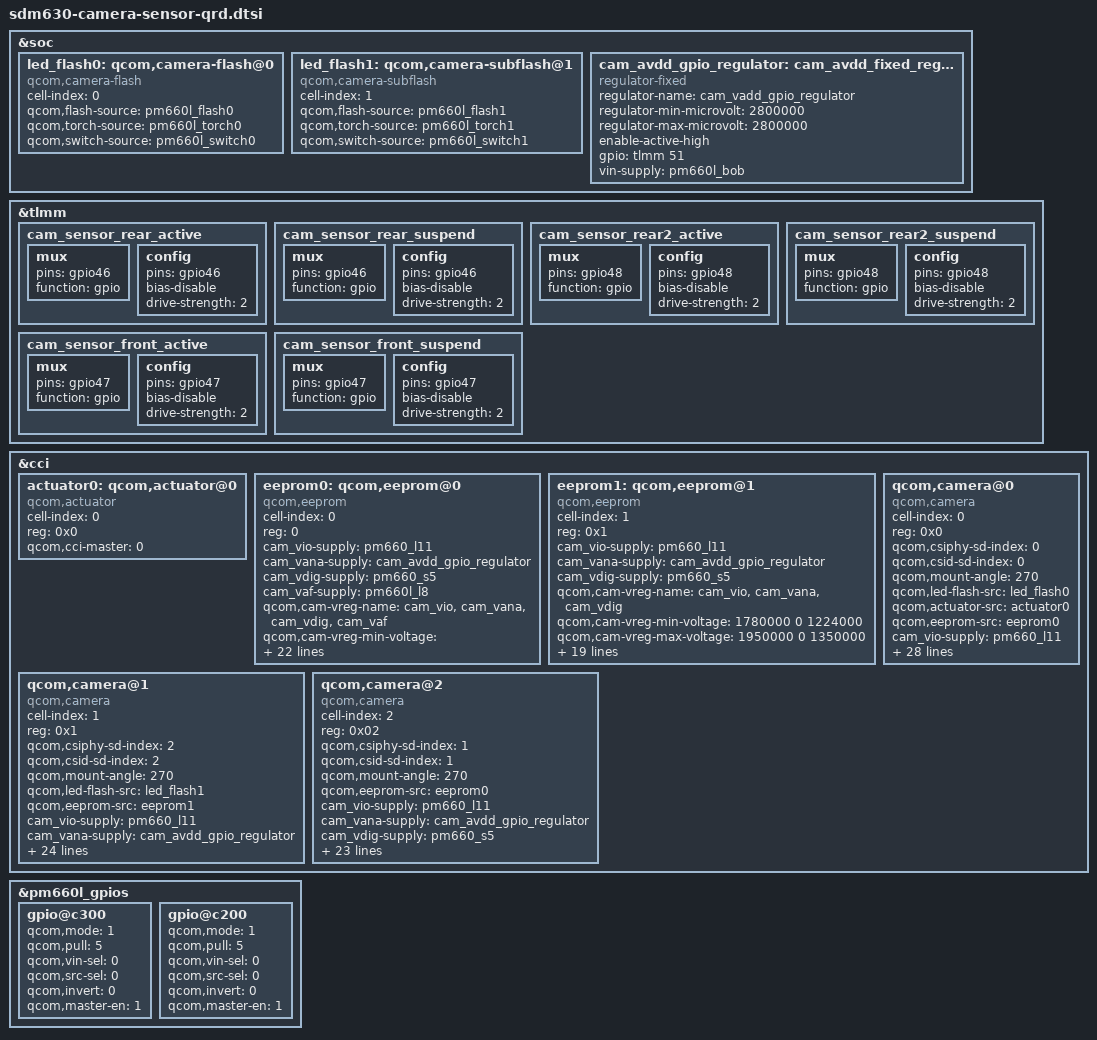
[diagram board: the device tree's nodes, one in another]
/*
 * Copyright (c) 2017, The Linux Foundation. All rights reserved.
 *
 * This program is free software; you can redistribute it and/or modify
 * it under the terms of the GNU General Public License version 2 and
 * only version 2 as published by the Free Software Foundation.
 *
 * This program is distributed in the hope that it will be useful,
 * but WITHOUT ANY WARRANTY; without even the implied warranty of
 * MERCHANTABILITY or FITNESS FOR A PARTICULAR PURPOSE.  See the
 * GNU General Public License for more details.
 */

&soc {

	led_flash0: qcom,camera-flash@0 {
		cell-index = <0>;
		compatible = "qcom,camera-flash";
		qcom,flash-source = <&pm660l_flash0>;
		qcom,torch-source = <&pm660l_torch0>;
		qcom,switch-source = <&pm660l_switch0>;
		status = "ok";
	};


	led_flash1: qcom,camera-subflash@1 {
		cell-index = <1>;
		compatible = "qcom,camera-subflash";
		qcom,flash-source = <&pm660l_flash1>;
		qcom,torch-source = <&pm660l_torch1>;
		qcom,switch-source = <&pm660l_switch1>;
		status = "ok";
	};


	cam_avdd_gpio_regulator: cam_avdd_fixed_regulator {
		compatible = "regulator-fixed";
		regulator-name = "cam_vadd_gpio_regulator";
		regulator-min-microvolt = <2800000>;
		regulator-max-microvolt = <2800000>;
		enable-active-high;
		gpio = <&tlmm 51 0>;
		vin-supply = <&pm660l_bob>;
	};

/*
	cam_vaf_gpio_regulator: cam_vaf_fixed_regulator {
		compatible = "regulator-fixed";
		regulator-name = "cam_vaf_gpio_regulator";
		regulator-min-microvolt = <2800000>;
		regulator-max-microvolt = <2800000>;
		enable-active-high;
		gpio = <&tlmm 50 0>;
		vin-supply = <&pm660l_bob>;
	};
*/
};

&tlmm {
	cam_sensor_rear_active: cam_sensor_rear_active {
		/* RESET */
		mux {
			pins = "gpio46";
			function = "gpio";
		};

		config {
			pins = "gpio46";
			bias-disable; /* No PULL */
			drive-strength = <2>; /* 2 MA */
		};
	};

	cam_sensor_rear_suspend: cam_sensor_rear_suspend {
		/* RESET */
		mux {
			pins = "gpio46";
			function = "gpio";
		};

		config {
			pins = "gpio46";
			bias-disable; /* No PULL */
			drive-strength = <2>; /* 2 MA */
		};
	};

	cam_sensor_rear2_active: cam_sensor_rear2_active {
		/* RESET */
		mux {
			pins = "gpio48";
			function = "gpio";
		};

		config {
			pins = "gpio48";
			bias-disable; /* No PULL */
			drive-strength = <2>; /* 2 MA */
		};
	};

	cam_sensor_rear2_suspend: cam_sensor_rear2_suspend {
		/* RESET */
		mux {
			pins = "gpio48";
			function = "gpio";
		};

		config {
			pins = "gpio48";
			bias-disable; /* No PULL */
			drive-strength = <2>; /* 2 MA */
		};
	};

	cam_sensor_front_active: cam_sensor_front_active {
		/* RESET */
		mux {
			pins = "gpio47";
			function = "gpio";
		};

		config {
			pins = "gpio47";
			bias-disable; /* No PULL */
			drive-strength = <2>; /* 2 MA */
		};
	};

	cam_sensor_front_suspend: cam_sensor_front_suspend {
		/* RESET */
		mux {
			pins = "gpio47";
			function = "gpio";
		};

		config {
			pins = "gpio47";
			bias-disable; /* No PULL */
			drive-strength = <2>; /* 2 MA */
		};
	};
};

&cci {
	actuator0: qcom,actuator@0 {
		cell-index = <0>;
		reg = <0x0>;
		compatible = "qcom,actuator";
		qcom,cci-master = <0>;
	};
/*
	actuator1: qcom,actuator@1 {
		cell-index = <1>;
		reg = <0x1>;
		compatible = "qcom,actuator";
		qcom,cci-master = <1>;
		cam_vaf-supply = <&cam_vaf_gpio_regulator>;
		qcom,cam-vreg-name = "cam_vaf";
		qcom,cam-vreg-min-voltage = <2800000>;
		qcom,cam-vreg-max-voltage = <2800000>;
		qcom,cam-vreg-op-mode = <0>;
	};

	ois0: qcom,ois {
		cell-index = <0>;
		compatible = "qcom,ois";
		qcom,cci-master = <0>;
		cam_vaf-supply = <&cam_vaf_gpio_regulator>;
		qcom,cam-vreg-name = "cam_vaf";
		qcom,cam-vreg-min-voltage = <2800000>;
		qcom,cam-vreg-max-voltage = <2800000>;
		qcom,cam-vreg-op-mode = <0>;
		status = "disabled";
	};
*/
	eeprom0: qcom,eeprom@0 {
		cell-index = <0>;
		reg = <0>;
		compatible = "qcom,eeprom";
		cam_vio-supply = <&pm660_l11>;
		cam_vana-supply = <&cam_avdd_gpio_regulator>;
		cam_vdig-supply = <&pm660_s5>;
		cam_vaf-supply = <&pm660l_l8>;
		qcom,cam-vreg-name = "cam_vio", "cam_vana", "cam_vdig", "cam_vaf";
		qcom,cam-vreg-min-voltage = <1780000 0 1224000 2800000>;
		qcom,cam-vreg-max-voltage = <1950000 0 1350000 2800000>;
		qcom,cam-vreg-op-mode = <105000 0 105000 100000>;
		qcom,gpio-no-mux = <0>;
		pinctrl-names = "cam_default", "cam_suspend";
		pinctrl-0 = <&cam_sensor_mclk0_active
				 &cam_sensor_rear_active>;
		pinctrl-1 = <&cam_sensor_mclk0_suspend
				 &cam_sensor_rear_suspend>;
		gpios = <&tlmm 32 0>,
			<&tlmm 46 0>,
			<&pm660l_gpios 4 0>;
		qcom,gpio-reset = <1>;
		qcom,gpio-vdig = <2>;
		qcom,gpio-req-tbl-num = <0 1 2>;
		qcom,gpio-req-tbl-flags = <1 0 0>;
		qcom,gpio-req-tbl-label = "CAMIF_MCLK0",
					"CAM_RESET0",
					"CAM_VDIG0";
		qcom,sensor-position = <0>;
		qcom,sensor-mode = <0>;
		qcom,cci-master = <0>;
		status = "ok";
		clocks = <&clock_mmss MCLK0_CLK_SRC>,
				<&clock_mmss MMSS_CAMSS_MCLK0_CLK>;
		clock-names = "cam_src_clk", "cam_clk";
		qcom,clock-rates = <24000000 0>;
	};

	eeprom1: qcom,eeprom@1 {
		cell-index = <1>;
		reg = <0x1>;
		compatible = "qcom,eeprom";
		cam_vio-supply = <&pm660_l11>;
		cam_vana-supply = <&cam_avdd_gpio_regulator>;
		cam_vdig-supply = <&pm660_s5>;
		qcom,cam-vreg-name = "cam_vio", "cam_vana", "cam_vdig";
		qcom,cam-vreg-min-voltage = <1780000 0 1224000>;
		qcom,cam-vreg-max-voltage = <1950000 0 1350000>;
		qcom,cam-vreg-op-mode = <105000 0 105000>;
		qcom,gpio-no-mux = <0>;
		pinctrl-names = "cam_default", "cam_suspend";
		pinctrl-0 = <&cam_sensor_mclk1_active
				 &cam_sensor_front_active>;
		pinctrl-1 = <&cam_sensor_mclk1_suspend
				 &cam_sensor_front_suspend>;
		gpios = <&tlmm 33 0>,
			<&tlmm 47 0>,
			<&pm660l_gpios 3 0>;
		qcom,gpio-reset = <1>;
		qcom,gpio-vdig = <2>;
		qcom,gpio-req-tbl-num = <0 1 2>;
		qcom,gpio-req-tbl-flags = <1 0 0>;
		qcom,gpio-req-tbl-label = "CAMIF_MCLK1",
					  "CAM_RESET1",
					  "CAM_VDIG1";
		qcom,sensor-position = <1>;
		qcom,sensor-mode = <0>;
		qcom,cci-master = <1>;
		status = "ok";
		clocks = <&clock_mmss MCLK1_CLK_SRC>,
			<&clock_mmss MMSS_CAMSS_MCLK1_CLK>;
		clock-names = "cam_src_clk", "cam_clk";
		qcom,clock-rates = <24000000 0>;
	};

/*
	eeprom2: qcom,eeprom@2 {
		cell-index = <2>;
		reg = <0x2>;
		compatible = "qcom,eeprom";
		cam_vio-supply = <&pm660_l11>;
		cam_vana-supply = <&cam_avdd_gpio_regulator>;
		cam_vdig-supply = <&pm660_s5>;
		qcom,cam-vreg-name = "cam_vio", "cam_vana", "cam_vdig";
		qcom,cam-vreg-min-voltage = <1780000 0 1352000>;
		qcom,cam-vreg-max-voltage = <1950000 0 1352000>;
		qcom,cam-vreg-op-mode = <105000 0 105000>;
		qcom,gpio-no-mux = <0>;
		pinctrl-names = "cam_default", "cam_suspend";
		pinctrl-0 = <&cam_sensor_mclk1_active
				 &cam_sensor_front_active>;
		pinctrl-1 = <&cam_sensor_mclk1_suspend
				 &cam_sensor_front_suspend>;
		gpios = <&tlmm 33 0>,
			<&tlmm 47 0>,
			<&pm660l_gpios 3 0>;
		qcom,gpio-reset = <1>;
		qcom,gpio-vdig = <2>;
		qcom,gpio-req-tbl-num = <0 1 2>;
		qcom,gpio-req-tbl-flags = <1 0 0>;
		qcom,gpio-req-tbl-label = "CAMIF_MCLK2",
					"CAM_RESET2",
					"CAM_VDIG";
		qcom,sensor-position = <1>;
		qcom,sensor-mode = <0>;
		qcom,cci-master = <1>;
		status = "ok";
		clocks = <&clock_mmss MCLK1_CLK_SRC>,
			<&clock_mmss MMSS_CAMSS_MCLK1_CLK>;
		clock-names = "cam_src_clk", "cam_clk";
		qcom,clock-rates = <24000000 0>;
	};
*/
	qcom,camera@0 {
		cell-index = <0>;
		compatible = "qcom,camera";
		reg = <0x0>;
		qcom,csiphy-sd-index = <0>;
		qcom,csid-sd-index = <0>;
		qcom,mount-angle = <270>;
		qcom,led-flash-src = <&led_flash0>;
		qcom,actuator-src = <&actuator0>;
		//qcom,ois-src = <&ois0>;
		qcom,eeprom-src = <&eeprom0>;
		cam_vio-supply = <&pm660_l11>;
		cam_vana-supply = <&cam_avdd_gpio_regulator>;
		cam_vdig-supply = <&pm660_s5>;
		cam_vaf-supply = <&pm660l_l8>;
		qcom,cam-vreg-name = "cam_vio", "cam_vana", "cam_vdig", "cam_vaf";
		/*Huaqin modify for af_vdd voltage by lizihao at 2015/02/05 start*/
		qcom,cam-vreg-min-voltage = <1780000 0 1224000 2800000>;
		qcom,cam-vreg-max-voltage = <1950000 0 1350000 2800000>;
		/*Huaqin modify for af_vdd voltage by lizihao at 2015/02/05 end*/
		qcom,cam-vreg-op-mode = <105000 0 105000 100000>;
		qcom,gpio-no-mux = <0>;
		pinctrl-names = "cam_default", "cam_suspend";
		pinctrl-0 = <&cam_sensor_mclk0_active
				 &cam_sensor_rear_active>;
		pinctrl-1 = <&cam_sensor_mclk0_suspend
				 &cam_sensor_rear_suspend>;
		gpios = <&tlmm 32 0>,
			<&tlmm 46 0>,
			<&pm660l_gpios 4 0>;
		qcom,gpio-reset = <1>;
		qcom,gpio-vdig = <2>;
		qcom,gpio-req-tbl-num = <0 1 2>;
		qcom,gpio-req-tbl-flags = <1 0 0>;
		qcom,gpio-req-tbl-label = "CAMIF_MCLK0",
					"CAM_RESET0",
					"CAM_VDIG0";
		qcom,sensor-position = <0>;
		qcom,sensor-mode = <0>;
		qcom,cci-master = <0>;
		status = "ok";
		clocks = <&clock_mmss MCLK0_CLK_SRC>,
				<&clock_mmss MMSS_CAMSS_MCLK0_CLK>;
		clock-names = "cam_src_clk", "cam_clk";
		qcom,clock-rates = <24000000 0>;
	};

	qcom,camera@1 {
		cell-index = <1>;
		compatible = "qcom,camera";
		reg = <0x1>;
		qcom,csiphy-sd-index = <2>;
		qcom,csid-sd-index = <2>;
		qcom,mount-angle = <270>;
		qcom,led-flash-src = <&led_flash1>;
		qcom,eeprom-src = <&eeprom1>;
		cam_vio-supply = <&pm660_l11>;
		cam_vana-supply = <&cam_avdd_gpio_regulator>;
		cam_vdig-supply = <&pm660_s5>;
		qcom,cam-vreg-name = "cam_vio", "cam_vana", "cam_vdig";
		/*Huaqin modify for af_vdd voltage by lizihao at 2015/02/05 start*/
		qcom,cam-vreg-min-voltage = <1780000 0 1224000>;
		qcom,cam-vreg-max-voltage = <1950000 0 1350000>;
		/*Huaqin modify for af_vdd voltage by lizihao at 2015/02/05 end*/
		qcom,cam-vreg-op-mode = <105000 0 105000>;
		qcom,gpio-no-mux = <0>;
		pinctrl-names = "cam_default", "cam_suspend";
		pinctrl-0 = <&cam_sensor_mclk1_active
				 &cam_sensor_front_active>;
		pinctrl-1 = <&cam_sensor_mclk1_suspend
				 &cam_sensor_front_suspend>;
		gpios = <&tlmm 33 0>,
			<&tlmm 47 0>,
			<&pm660l_gpios 3 0>;
		qcom,gpio-reset = <1>;
		qcom,gpio-vdig = <2>;
		qcom,gpio-req-tbl-num = <0 1 2>;
		qcom,gpio-req-tbl-flags = <1 0 0>;
		qcom,gpio-req-tbl-label = "CAMIF_MCLK1",
					  "CAM_RESET1",
					  "CAM_VDIG1";
		qcom,sensor-position = <1>;
		qcom,sensor-mode = <0>;
		qcom,cci-master = <1>;
		status = "ok";
		clocks = <&clock_mmss MCLK1_CLK_SRC>,
			<&clock_mmss MMSS_CAMSS_MCLK1_CLK>;
		clock-names = "cam_src_clk", "cam_clk";
		qcom,clock-rates = <24000000 0>;
	};

/* Huaqin modify for add sub camera dts config by lizihao at 2018/02/11 start*/
	qcom,camera@2 {
		cell-index = <2>;
		compatible = "qcom,camera";
		reg = <0x02>;
		qcom,csiphy-sd-index = <1>;
		qcom,csid-sd-index = <1>;
		qcom,mount-angle = <270>;
		/* Huaqin add for gc5025 eeprom by lizihao at 2018/03/23 start*/
		qcom,eeprom-src = <&eeprom0>;
		/* Huaqin add for gc5025 eeprom by lizihao at 2018/03/23 end*/
		cam_vio-supply = <&pm660_l11>;
		cam_vana-supply = <&cam_avdd_gpio_regulator>;
		cam_vdig-supply = <&pm660_s5>;
		qcom,cam-vreg-name = "cam_vio", "cam_vana", "cam_vdig";
		qcom,cam-vreg-min-voltage = <1780000 0 1224000>;
		qcom,cam-vreg-max-voltage = <1950000 0 1350000>;
		qcom,cam-vreg-op-mode = <105000 0 105000>;
		qcom,gpio-no-mux = <0>;
		pinctrl-names = "cam_default", "cam_suspend";
		pinctrl-0 = <&cam_sensor_mclk3_active
				 &cam_sensor_rear2_active>;
		pinctrl-1 = <&cam_sensor_mclk3_suspend
				 &cam_sensor_rear2_suspend>;
		gpios = <&tlmm 35 0>,
			<&tlmm 48 0>,
			<&pm660l_gpios 4 0>;
		qcom,gpio-reset = <1>;
		qcom,gpio-vdig = <2>;
		qcom,gpio-req-tbl-num = <0 1 2>;
		qcom,gpio-req-tbl-flags = <1 0 0>;
		qcom,gpio-req-tbl-label = "CAMIF_MCLK2",
					"CAM_RESET2",
					"CAM_VDIG2";
		qcom,sensor-position = <0>;
		qcom,sensor-mode = <0>;
		qcom,cci-master = <1>;
		status = "ok";
		clocks = <&clock_mmss MCLK3_CLK_SRC>,
			<&clock_mmss MMSS_CAMSS_MCLK3_CLK>;
		clock-names = "cam_src_clk", "cam_clk";
		qcom,clock-rates = <24000000 0>;
	};
/* Huaqin modify for add sub camera dts config by lizihao at 2018/02/11 end*/

};

&pm660l_gpios {
	gpio@c300 { /* GPIO4 -CAMERA SENSOR 0 VDIG*/
		qcom,mode = <1>;                /* Output */
		qcom,pull = <5>;                /* No Pull */
		qcom,vin-sel = <0>;             /* VIN1 GPIO_LV */
		qcom,src-sel = <0>;             /* GPIO */
		qcom,invert = <0>;              /* Invert */
		qcom,master-en = <1>;           /* Enable GPIO */
		status = "ok";
	};

	gpio@c200 { /* GPIO3 -CAMERA SENSOR 2 VDIG*/
		qcom,mode = <1>;                /* Output */
		qcom,pull = <5>;                /* No Pull */
		qcom,vin-sel = <0>;             /* VIN1 GPIO_LV */
		qcom,src-sel = <0>;             /* GPIO */
		qcom,invert = <0>;              /* Invert */
		qcom,master-en = <1>;           /* Enable GPIO */
		status = "ok";
	};
};
